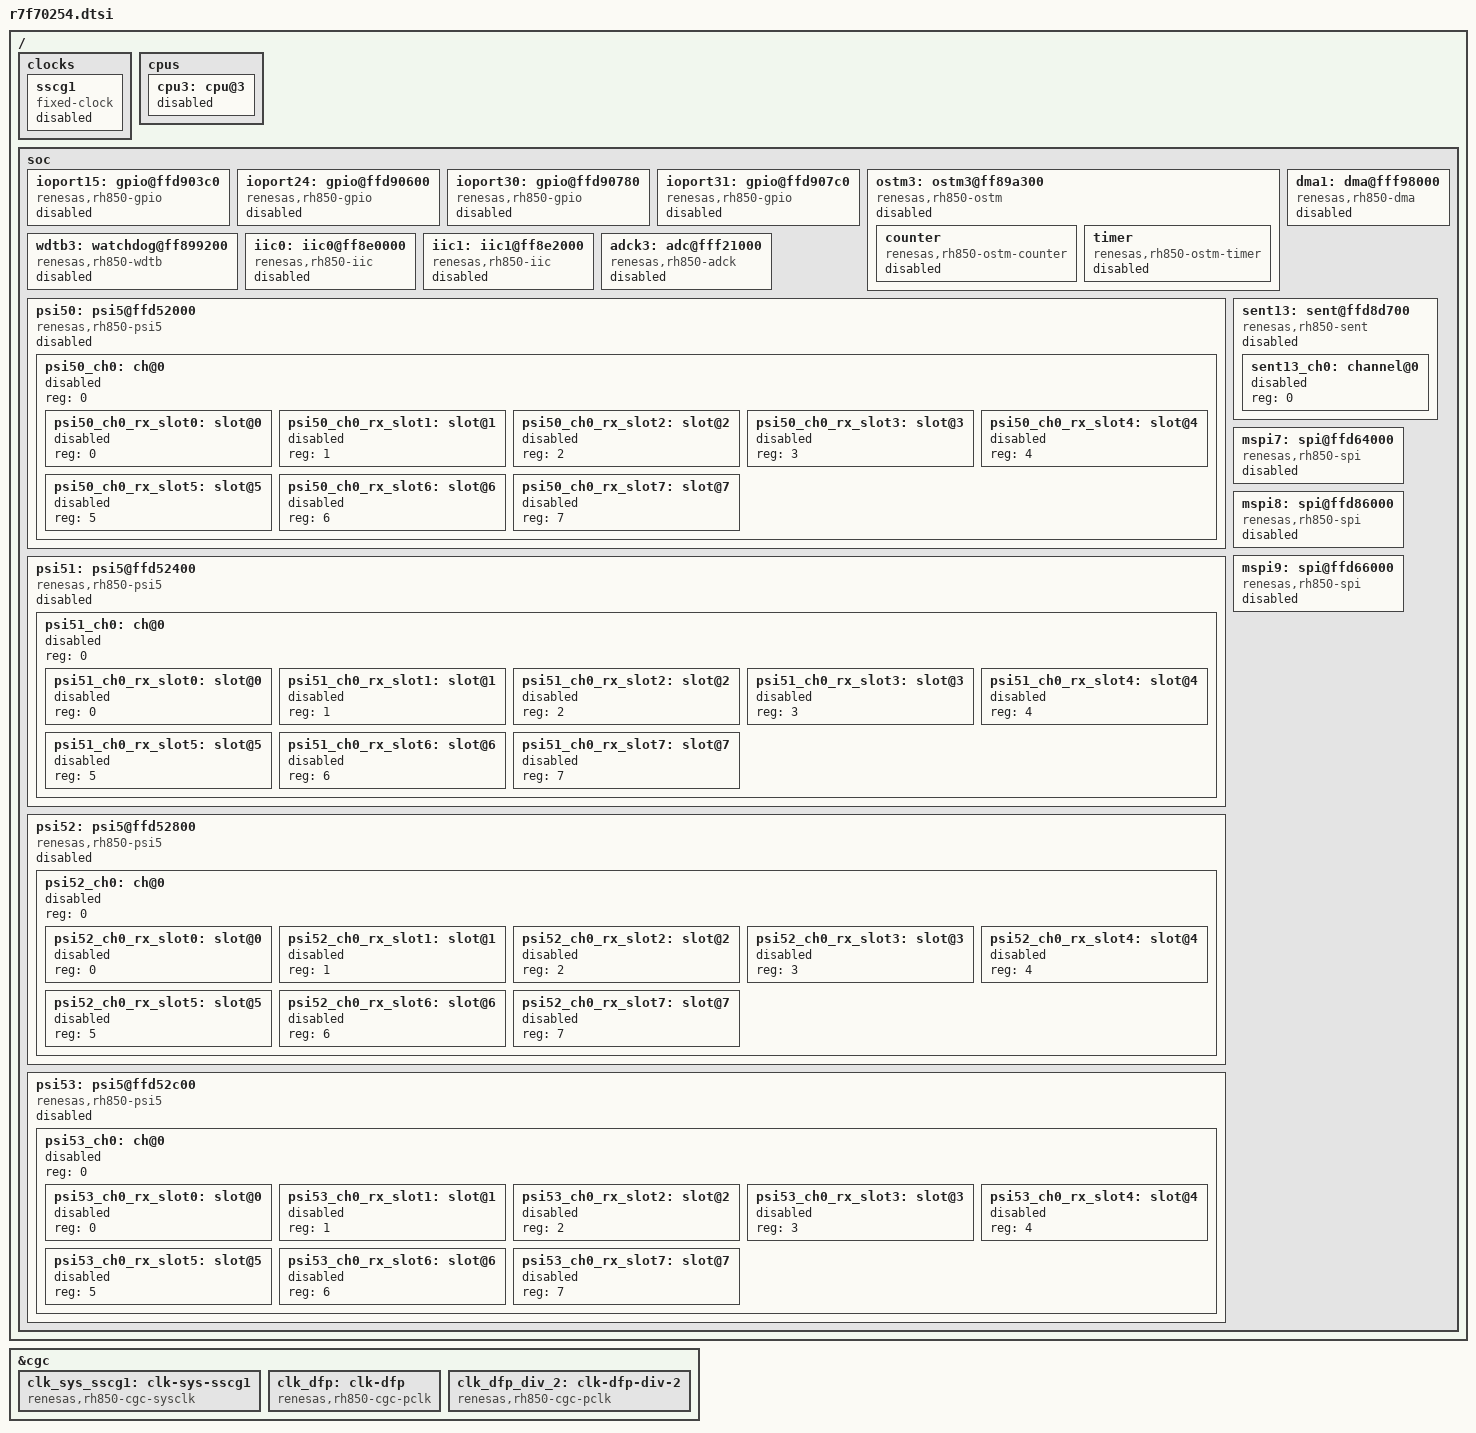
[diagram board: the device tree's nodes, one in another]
/*
 * Copyright (c) 2026 Renesas Electronics Corporation
 *
 * SPDX-License-Identifier: Apache-2.0
 */

#include <rh850/renesas/rh850u2b/r7f70255.dtsi>

/* Peripheral definition following RH850/U2B10 devices */
/ {
	clocks {
		sscg1: sscg1 {
			compatible = "fixed-clock";
			#clock-cells = <0>;
			status = "disabled";
			clock-frequency = <0>;
			clocks = <&mosc>;
		};
	};
};

&cgc {
	clk_sys_sscg1: clk-sys-sscg1 {
		compatible = "renesas,rh850-cgc-sysclk";
		clock-source = <&iosc>;
		#clock-cells = <0>;
		status = "okay";
		modulation-value = <30>;
		modulation-dithered-range = <0>;
		div = <1>;
	};

	clk_dfp: clk-dfp {
		compatible = "renesas,rh850-cgc-pclk";
		#clock-cells = <0>;
		status = "okay";
		clock-source = <&clk_sys_sscg1>;
		div = <2>;
	};

	clk_dfp_div_2: clk-dfp-div-2 {
		compatible = "renesas,rh850-cgc-pclk";
		#clock-cells = <0>;
		status = "okay";
		clock-source = <&clk_dfp>;
		div = <2>;
	};
};

/ {
	cpus {
		cpu3: cpu@3 {
			status = "disabled";
		};
	};

	soc {
		ioport15: gpio@ffd903c0 {
			compatible = "renesas,rh850-gpio";
			reg = <0xffd903c0 0x40>;
			port = <15>;
			protected-write-mask = <8>;
			port-type = "port";
			#gpio-cells = <2>;
			gpio-controller;
			status = "disabled";
		};

		ioport24: gpio@ffd90600 {
			compatible = "renesas,rh850-gpio";
			reg = <0xffd90600 0x40>;
			port = <24>;
			protected-write-mask = <13>;
			port-type = "port";
			#gpio-cells = <2>;
			gpio-controller;
			status = "disabled";
		};

		ioport30: gpio@ffd90780 {
			compatible = "renesas,rh850-gpio";
			reg = <0xffd90780 0x40>;
			port = <30>;
			protected-write-mask = <17>;
			port-type = "port";
			#gpio-cells = <2>;
			gpio-controller;
			status = "disabled";
		};

		ioport31: gpio@ffd907c0 {
			compatible = "renesas,rh850-gpio";
			reg = <0xffd907c0 0x40>;
			port = <31>;
			protected-write-mask = <18>;
			port-type = "port";
			#gpio-cells = <2>;
			gpio-controller;
			status = "disabled";
		};

		ostm3: ostm3@ff89a300 {
			compatible = "renesas,rh850-ostm";
			reg = <0xff89a300 0x20>;
			channel = <3>;
			interrupt-names = "overflow";
			interrupts = <842 1>;
			interrupt-parent = <&intc2>;
			clocks = <&cgc RH850_PCLK(OSTM, 3, PCLK)>;
			status = "disabled";

			counter {
				compatible = "renesas,rh850-ostm-counter";
				status = "disabled";
			};

			timer {
				compatible = "renesas,rh850-ostm-timer";
				status = "disabled";
			};
		};

		wdtb3: watchdog@ff899200 {
			unit = <4>;
			compatible = "renesas,rh850-wdtb";
			interrupts = <22 0>;
			window-open-mode = "select-by-window-start";
			error-mode = "nmi-mode";
			clock-freq = <312500>;
			reg = <0xff899200 0x14>;
			interrupt-parent = <&intc2>;
			status = "disabled";
		};

		iic0: iic0@ff8e0000 {
			compatible = "renesas,rh850-iic";
			interrupts = <882 1>, <883 1>, <886 1>, <887 1>;
			interrupt-names = "rxi", "txi", "eri", "tei";
			reg = <0xff8e0000 0x2000>;
			interrupt-parent = <&intc2>;
			clocks = <&cgc RH850_PCLK(RIIC, 0, LSB)>;
			#address-cells = <1>;
			#size-cells = <0>;
			channel = <0>;
			status = "disabled";
		};

		iic1: iic1@ff8e2000 {
			compatible = "renesas,rh850-iic";
			interrupts = <884 1>, <885 1>, <888 1>, <889 1>;
			interrupt-names = "rxi", "txi", "eri", "tei";
			reg = <0xff8e2000 0x2000>;
			interrupt-parent = <&intc2>;
			clocks = <&cgc RH850_PCLK(RIIC, 1, LSB)>;
			#address-cells = <1>;
			#size-cells = <0>;
			channel = <1>;
			status = "disabled";
		};

		dma1: dma@fff98000 {
			compatible = "renesas,rh850-dma";
			reg = <0xfff98000 0x5000>, <0xfff9d000 0x020>;
			reg-names = "reg_main", "ext";
			interrupts = <825 1>, <826 1>, <827 1>, <828 1>,
				     <829 1>, <830 1>, <831 1>, <832 1>,
				     <833 1>, <834 1>, <835 1>, <836 1>,
				     <837 1>, <838 1>, <839 1>, <840 1>;
			interrupt-names = "ch0", "ch1", "ch2", "ch3",
					  "ch4", "ch5", "ch6", "ch7",
					  "ch8", "ch9", "ch10", "ch11",
					  "ch12", "ch13", "ch14", "ch15";
			interrupt-parent = <&intc2>;
			dma-unit = <1>;
			dma-channels = <16>;
			#dma-cells = <3>;
			status = "disabled";
		};

		adck3: adc@fff21000 {
			compatible = "renesas,rh850-adck";
			reg = <0xfff21000 0x1000>;
			interrupts = <456 1>, <457 1>, <458 1>, <459 1>, <460 1>, <464 1>;
			interrupt-names = "sg0", "sg1", "sg2", "sg3", "sg4", "error";
			interrupt-parent = <&intc2>;
			clocks = <&cgc RH850_PCLK(ADCK_ISO, 3, ADCK)>,
				 <&cgc RH850_PCLK(ADCK_ISO, 4, ADCK)>,
				 <&cgc RH850_PCLK(ADCK_ISO, 5, ADCK)>,
				 <&cgc RH850_PCLK(ADCK_ISO, 6, ADCK)>,
				 <&cgc RH850_PCLK(ADCK_ISO, 7, ADCK)>;
			#io-channel-cells = <1>;
			#address-cells = <1>;
			#size-cells = <0>;
			renesas,unit = <3>;
			renesas,physical-channel-mask = <0xffffffff 0x00000000>;
			renesas,th-supported-mask = <0x0f>;
			status = "disabled";
		};

		psi50: psi5@ffd52000 {
			compatible = "renesas,rh850-psi5";
			reg = <0xffd52000 0x400>;
			interrupts = <930 1>, <931 1>, <932 1>;
			interrupt-names = "status", "rx", "tx";
			interrupt-parent = <&intc2>;
			clocks = <&cgc RH850_PCLK(PSI5, 0, PCLK)>;
			renesas,unit-id = <0>;
			#address-cells = <1>;
			#size-cells = <0>;
			status = "disabled";

			psi50_ch0: ch@0 {
				reg = <0>;
				#address-cells = <1>;
				#size-cells = <0>;
				status = "disabled";

				psi50_ch0_rx_slot0: slot@0 {
					reg = <0>;
					status = "disabled";
				};

				psi50_ch0_rx_slot1: slot@1 {
					reg = <1>;
					status = "disabled";
				};

				psi50_ch0_rx_slot2: slot@2 {
					reg = <2>;
					status = "disabled";
				};

				psi50_ch0_rx_slot3: slot@3 {
					reg = <3>;
					status = "disabled";
				};

				psi50_ch0_rx_slot4: slot@4 {
					reg = <4>;
					status = "disabled";
				};

				psi50_ch0_rx_slot5: slot@5 {
					reg = <5>;
					status = "disabled";
				};

				psi50_ch0_rx_slot6: slot@6 {
					reg = <6>;
					status = "disabled";
				};

				psi50_ch0_rx_slot7: slot@7 {
					reg = <7>;
					status = "disabled";
				};
			};
		};

		psi51: psi5@ffd52400 {
			compatible = "renesas,rh850-psi5";
			reg = <0xffd52400 0x400>;
			interrupts = <933 1>, <934 1>, <935 1>;
			interrupt-names = "status", "rx", "tx";
			interrupt-parent = <&intc2>;
			clocks = <&cgc RH850_PCLK(PSI5, 1, PCLK)>;
			renesas,unit-id = <1>;
			#address-cells = <1>;
			#size-cells = <0>;
			status = "disabled";

			psi51_ch0: ch@0 {
				reg = <0>;
				#address-cells = <1>;
				#size-cells = <0>;
				status = "disabled";

				psi51_ch0_rx_slot0: slot@0 {
					reg = <0>;
					status = "disabled";
				};

				psi51_ch0_rx_slot1: slot@1 {
					reg = <1>;
					status = "disabled";
				};

				psi51_ch0_rx_slot2: slot@2 {
					reg = <2>;
					status = "disabled";
				};

				psi51_ch0_rx_slot3: slot@3 {
					reg = <3>;
					status = "disabled";
				};

				psi51_ch0_rx_slot4: slot@4 {
					reg = <4>;
					status = "disabled";
				};

				psi51_ch0_rx_slot5: slot@5 {
					reg = <5>;
					status = "disabled";
				};

				psi51_ch0_rx_slot6: slot@6 {
					reg = <6>;
					status = "disabled";
				};

				psi51_ch0_rx_slot7: slot@7 {
					reg = <7>;
					status = "disabled";
				};
			};
		};

		psi52: psi5@ffd52800 {
			compatible = "renesas,rh850-psi5";
			reg = <0xffd52800 0x400>;
			interrupts = <936 1>, <937 1>, <938 1>;
			interrupt-names = "status", "rx", "tx";
			interrupt-parent = <&intc2>;
			clocks = <&cgc RH850_PCLK(PSI5, 2, PCLK)>;
			renesas,unit-id = <2>;
			#address-cells = <1>;
			#size-cells = <0>;
			status = "disabled";

			psi52_ch0: ch@0 {
				reg = <0>;
				#address-cells = <1>;
				#size-cells = <0>;
				status = "disabled";

				psi52_ch0_rx_slot0: slot@0 {
					reg = <0>;
					status = "disabled";
				};

				psi52_ch0_rx_slot1: slot@1 {
					reg = <1>;
					status = "disabled";
				};

				psi52_ch0_rx_slot2: slot@2 {
					reg = <2>;
					status = "disabled";
				};

				psi52_ch0_rx_slot3: slot@3 {
					reg = <3>;
					status = "disabled";
				};

				psi52_ch0_rx_slot4: slot@4 {
					reg = <4>;
					status = "disabled";
				};

				psi52_ch0_rx_slot5: slot@5 {
					reg = <5>;
					status = "disabled";
				};

				psi52_ch0_rx_slot6: slot@6 {
					reg = <6>;
					status = "disabled";
				};

				psi52_ch0_rx_slot7: slot@7 {
					reg = <7>;
					status = "disabled";
				};
			};
		};

		psi53: psi5@ffd52c00 {
			compatible = "renesas,rh850-psi5";
			reg = <0xffd52c00 0x400>;
			interrupts = <939 1>, <940 1>, <941 1>;
			interrupt-names = "status", "rx", "tx";
			interrupt-parent = <&intc2>;
			clocks = <&cgc RH850_PCLK(PSI5, 3, PCLK)>;
			renesas,unit-id = <3>;
			#address-cells = <1>;
			#size-cells = <0>;
			status = "disabled";

			psi53_ch0: ch@0 {
				reg = <0>;
				#address-cells = <1>;
				#size-cells = <0>;
				status = "disabled";

				psi53_ch0_rx_slot0: slot@0 {
					reg = <0>;
					status = "disabled";
				};

				psi53_ch0_rx_slot1: slot@1 {
					reg = <1>;
					status = "disabled";
				};

				psi53_ch0_rx_slot2: slot@2 {
					reg = <2>;
					status = "disabled";
				};

				psi53_ch0_rx_slot3: slot@3 {
					reg = <3>;
					status = "disabled";
				};

				psi53_ch0_rx_slot4: slot@4 {
					reg = <4>;
					status = "disabled";
				};

				psi53_ch0_rx_slot5: slot@5 {
					reg = <5>;
					status = "disabled";
				};

				psi53_ch0_rx_slot6: slot@6 {
					reg = <6>;
					status = "disabled";
				};

				psi53_ch0_rx_slot7: slot@7 {
					reg = <7>;
					status = "disabled";
				};
			};
		};

		sent13: sent@ffd8d700 {
			compatible = "renesas,rh850-sent";
			reg = <0xffd8d700 0x64>;
			unit = <13>;
			interrupts = <893 1>, <913 1>;
			interrupt-names = "rxi", "eri";
			interrupt-parent = <&intc2>;
			clocks = <&cgc RH850_PCLK(RSENT, 13, HSB)>;
			#address-cells = <1>;
			#size-cells = <0>;
			status = "disabled";

			sent13_ch0: channel@0 {
				reg = <0>;
				status = "disabled";
			};
		};

		mspi7: spi@ffd64000 {
			compatible = "renesas,rh850-spi";
			interrupts = <851 1>, <852 1>, <853 1>, <854 1>;
			interrupt-names = "txi", "rxi", "tei", "eri";
			clocks = <&cgc RH850_PCLK(MSPI, 7, MSPI)>;
			reg = <0xffd64000 0x680>;
			interrupt-parent = <&intc2>;
			#address-cells = <1>;
			#size-cells = <0>;
			unit = <7>;
			channel = <0>;
			status = "disabled";
		};

		mspi8: spi@ffd86000 {
			compatible = "renesas,rh850-spi";
			interrupts = <855 1>, <856 1>, <857 1>, <858 1>;
			interrupt-names = "txi", "rxi", "tei", "eri";
			clocks = <&cgc RH850_PCLK(MSPI, 8, MSPI)>;
			reg = <0xffd86000 0x680>;
			interrupt-parent = <&intc2>;
			#address-cells = <1>;
			#size-cells = <0>;
			unit = <8>;
			channel = <0>;
			status = "disabled";
		};

		mspi9: spi@ffd66000 {
			compatible = "renesas,rh850-spi";
			interrupts = <859 1>, <860 1>, <861 1>, <862 1>;
			interrupt-names = "txi", "rxi", "tei", "eri";
			clocks = <&cgc RH850_PCLK(MSPI, 9, MSPI)>;
			reg = <0xffd66000 0x680>;
			interrupt-parent = <&intc2>;
			#address-cells = <1>;
			#size-cells = <0>;
			unit = <9>;
			channel = <0>;
			status = "disabled";
		};
	};
};
